# FRONT_END register map
Vendor: Texas Instruments
Peripheral module from a debugger description file (folder ucd3138064).
Registers are 32-bit, access not given, no defined reset value unless marked. A register's access mark holds for its fields unless they carry their own. Offsets are as the file gives them; lines under a group give offsets from that group; [hi:lo] are bit positions; {n}, {i} and the like mark numbered series; 'fields as' and 'values as' point back to an identical list; <NAME> marks a mode.

## FECTRL
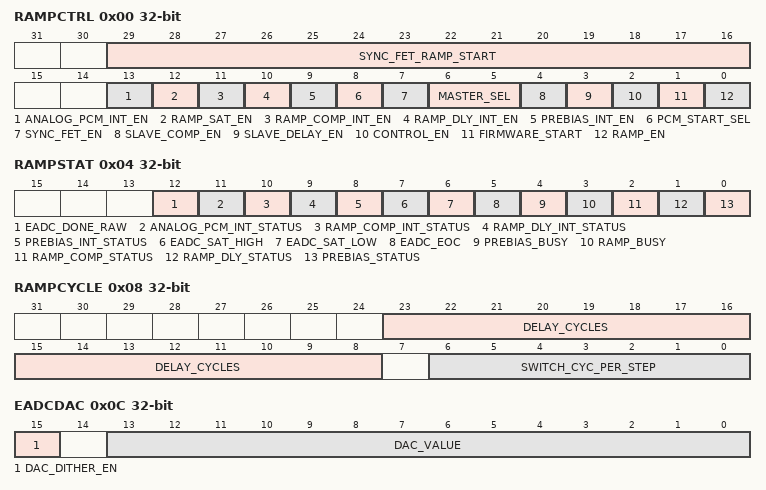
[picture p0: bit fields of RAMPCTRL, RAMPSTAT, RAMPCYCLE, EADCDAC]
0x00 RAMPCTRL — Ramp Control Register
  [29:16] SYNC_FET_RAMP_START rw — SyncFET Ramp Start Value
  [13] ANALOG_PCM_INT_EN rw — Analog Peak Current Interrupt Enable
  [12] RAMP_SAT_EN rw — Ramp Saturation Enable
  [11] RAMP_COMP_INT_EN rw — Ramp Complete Interrupt Enable
  [10] RAMP_DLY_INT_EN rw — Ramp Delay Complete Interrupt Enable
  [9] PREBIAS_INT_EN rw — Pre-Bias Complete Interrupt Enable
  [8] PCM_START_SEL rw — Peak Current Mode Start Select
  [7] SYNC_FET_EN rw — Enable use of Ramp for SyncFET
  [6:5] MASTER_SEL rw — Master Ramp I/F Select
  [4] SLAVE_COMP_EN rw — Sync ramp to Master Complete
  [3] SLAVE_DELAY_EN rw — Sync ramp to Master Delay Complete
  [2] CONTROL_EN rw — Sync ramp to Control assertion
  [1] FIRMWARE_START rw — Start ramp with firmware
  [0] RAMP_EN rw — Ramp Enable
0x04 RAMPSTAT — Ramp Status Register
  [12] EADC_DONE_RAW ro — EADC Conversion Raw Status
  [11] ANALOG_PCM_INT_STATUS ro — Analog Peak Current Latched Status
  [10] RAMP_COMP_INT_STATUS ro — Ramp Complete Latched Status
  [9] RAMP_DLY_INT_STATUS ro — Ramp Delay Complete Latched Status
  [8] PREBIAS_INT_STATUS ro — Prebias Complete Latched Status
  [7] EADC_SAT_HIGH ro — EADC Saturation High
  [6] EADC_SAT_LOW ro — EADC Saturation Low
  [5] EADC_EOC ro — EADC End of Conversion
  [4] PREBIAS_BUSY ro — Prebias Busy Indication
  [3] RAMP_BUSY ro — Ramp Busy Indication
  [2] RAMP_COMP_STATUS ro — Ramp Complete Indication
  [1] RAMP_DLY_STATUS ro — Ramp Delay Indication
  [0] PREBIAS_STATUS ro — Prebias Indication
0x08 RAMPCYCLE
  [23:8] DELAY_CYCLES rw — Number of Delay Cycles before ramp
  [6:0] SWITCH_CYC_PER_STEP rw — Number of switching cycles per step
0x0C EADCDAC — EADC DAC Value Register
  [15] DAC_DITHER_EN rw — DAC Dithering Enable
  [13:0] DAC_VALUE rw
0x10 RAMPDACEND — Ramp DAC Ending Value Register
  [13:0] RAMP_DAC_VALUE rw — Ramp Ending DAC Value
0x14 DACSTEP
  [17:0] DAC_STEP rw
0x18 DACSATSTEP — DAC Saturation Step Register
  [13:0] DAC_SAT_STEP rw — DAC SaturationStep
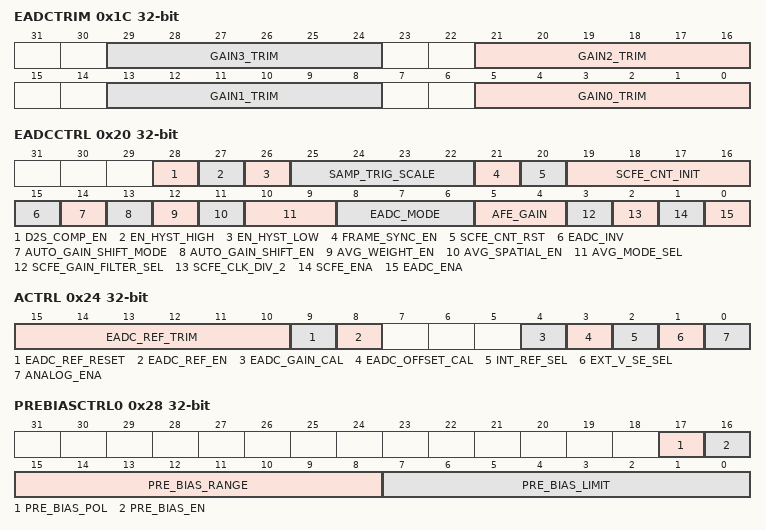
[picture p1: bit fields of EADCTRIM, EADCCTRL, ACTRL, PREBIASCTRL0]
0x1C EADCTRIM
  [8n+5:8n] GAIN{n}_TRIM rw (n=0..3)
0x20 EADCCTRL — EADC Control Register
  [28] D2S_COMP_EN rw — Analog Front End Ramp Comparator Enable
  [27] EN_HYST_HIGH rw — Increase comparator trip point
  [26] EN_HYST_LOW rw — Decrease comparator trip point
  [25:22] SAMP_TRIG_SCALE rw — Sample Trigger Scale
  [21] FRAME_SYNC_EN rw — Frame Sync Enable
  [20] SCFE_CNT_RST rw — Switched Cap Front End Counter Reset
  [19:16] SCFE_CNT_INIT rw — Initial Value for Switched Cap Front End Counter
  [15] EADC_INV rw — Invert EADC Data
  [14] AUTO_GAIN_SHIFT_MODE rw — Auto Gain Shifting Mode Select
  [13] AUTO_GAIN_SHIFT_EN rw — Auto Gain Shifting Enable
  [12] AVG_WEIGHT_EN rw — Averaging Weight Enable
  [11] AVG_SPATIAL_EN rw — Averaging Spatial Enable
  [10:9] AVG_MODE_SEL rw — Averaging Mode Select
  [8:6] EADC_MODE rw — EADC Mode Select
  [5:4] AFE_GAIN rw — AFE Gain Setting
  [3] SCFE_GAIN_FILTER_SEL rw — SCFE Gain Filter Enable
  [2] SCFE_CLK_DIV_2 rw — Front End sampling select
  [1] SCFE_ENA rw — SCFE Enable
  [0] EADC_ENA rw — EADC Enable
0x24 ACTRL — Analog Control Register
  [15:10] EADC_REF_TRIM rw — EADC Reference Trim
  [9] EADC_REF_RESET rw — EADC Reference Reset
  [8] EADC_REF_EN rw — EADC Reference Enable
  [4] EADC_GAIN_CAL rw — EADC Gain Calibration
  [3] EADC_OFFSET_CAL rw — EADC Offset Calibration
  [2] INT_REF_SEL rw — Internal Reference Select
  [1] EXT_V_SE_SEL rw — Selects V_SE
  [0] ANALOG_ENA rw — Analog Front Enable
0x28 PREBIASCTRL0 — Pre-bias Control Register 0
  [17] PRE_BIAS_POL rw — Prebias polarity
  [16] PRE_BIAS_EN rw — Prebias Enable
  [15:8] PRE_BIAS_RANGE rw
  [7:0] PRE_BIAS_LIMIT rw
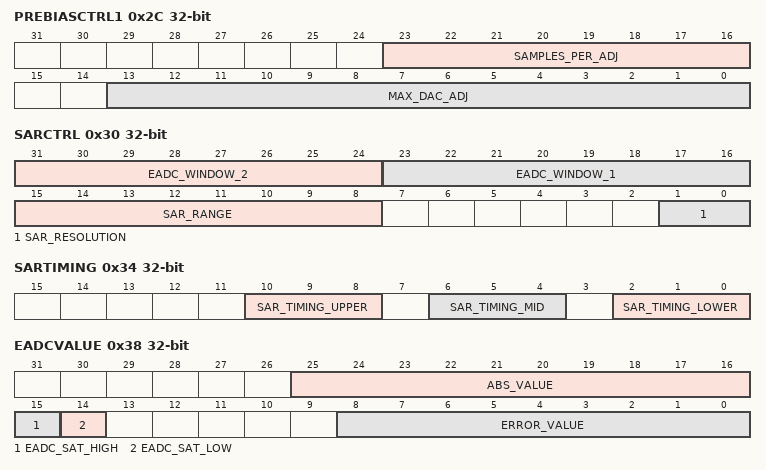
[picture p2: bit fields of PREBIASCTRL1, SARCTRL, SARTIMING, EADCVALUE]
0x2C PREBIASCTRL1 — Pre-bias Control Register 1
  [23:16] SAMPLES_PER_ADJ rw — Samples per adjustment
  [13:0] MAX_DAC_ADJ rw — Maximum DAC Adjustment
0x30 SARCTRL — SAR Control Register
  [31:24] EADC_WINDOW_2 rw — EADC Window 2 Setting
  [23:16] EADC_WINDOW_1 rw — EADC Window 1 Setting
  [15:8] SAR_RANGE rw — SAR Range Setting
  [1:0] SAR_RESOLUTION rw — SAR Final Resolution
0x34 SARTIMING
  [10:8] SAR_TIMING_UPPER rw — SAR Timing setting for upper bits
  [6:4] SAR_TIMING_MID rw — SAR Timing setting for mid bits
  [2:0] SAR_TIMING_LOWER rw — SAR Timing setting for lower bits
0x38 EADCVALUE
  [25:16] ABS_VALUE ro — Absolute Value
  [15] EADC_SAT_HIGH ro — Saturation High Indicator
  [14] EADC_SAT_LOW ro — Saturation Low Indicator
  [8:0] ERROR_VALUE ro
0x3C EADCRAWVALUE
  [8:0] RAW_ERROR_VALUE ro
0x40 DACSTAT — Current DAC Value Register
  [9:0] DAC_VALUE ro — Current DAC Value
